# MSP430FR5739 register map
File version: 1.1
CPU: msp430
Registers are 16-bit, access not given, reset 0x0 unless marked. A register's access mark holds for its fields unless they carry their own. Offsets are from the block's base; [hi:lo] are bit positions; {n}, {i} and the like mark numbered series.

## CS__Clock_System
Base 0x00000000
0x160 CSCTL0 — CS Control Register 0
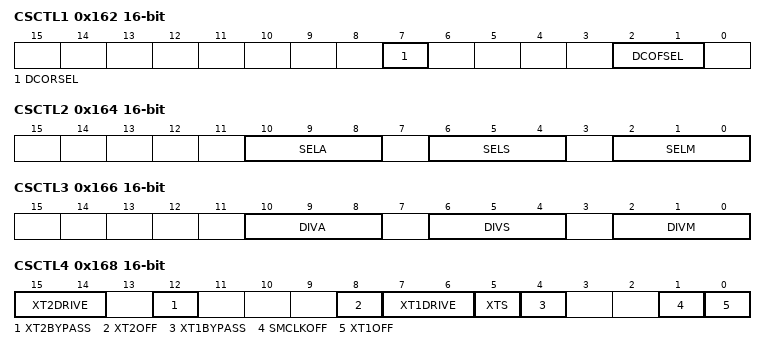
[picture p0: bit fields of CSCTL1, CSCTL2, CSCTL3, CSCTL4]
0x162 CSCTL1 — CS Control Register 1
  [7] DCORSEL — [7:7] DCO range select.
  [2:1] DCOFSEL — [2:1] DCO frequency select Bit: 0
    {v}=DCO frequency select: {v} (v=0..3)
0x164 CSCTL2 — CS Control Register 2
  [10:8] SELA — [10:8] ACLK Source Select Bit: 0
    {v}=ACLK Source Select {v} (v=0..7)
  [6:4] SELS — [6:4] SMCLK Source Select Bit: 0
    {v}=SMCLK Source Select {v} (v=0..7)
  [2:0] SELM — [2:0] MCLK Source Select Bit: 0
    {v}=MCLK Source Select {v} (v=0..7)
0x166 CSCTL3 — CS Control Register 3
  [10:8] DIVA — [10:8] ACLK Divider Bit: 0
    {v}=ACLK Source Divider {v} (v=0..5)
  [6:4] DIVS — [6:4] SMCLK Divider Bit: 0
    {v}=SMCLK Source Divider {v} (v=0..5)
  [2:0] DIVM — [2:0] MCLK Divider Bit: 0
    {v}=MCLK Source Divider {v} (v=0..5)
0x168 CSCTL4 — CS Control Register 4
  [15:14] XT2DRIVE — [15:14] XT2 Drive Level mode Bit 0
    {v}=XT2 Drive Level mode: {v} (v=0..3)
  [12] XT2BYPASS — [12:12] XT2 bypass mode : 0: internal 1:sourced from external pin
  [8] XT2OFF — [8:8] High Frequency Oscillator 2 (XT2) disable
  [7:6] XT1DRIVE — [7:6] XT1 Drive Level mode Bit 0
    {v}=XT1 Drive Level mode: {v} (v=0..3)
  [5] XTS — [5:5] 1: Selects high-freq. oscillator
  [4] XT1BYPASS — [4:4] XT1 bypass mode : 0: internal 1:sourced from external pin
  [1] SMCLKOFF — [1:1] SMCLK Off
  [0] XT1OFF — [0:0] High Frequency Oscillator 1 (XT1) disable
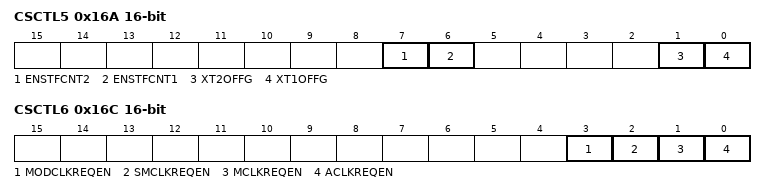
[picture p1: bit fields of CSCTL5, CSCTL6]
0x16A CSCTL5 — CS Control Register 5
  [7] ENSTFCNT2 — [7:7] Enable start counter for XT2
  [6] ENSTFCNT1 — [6:6] Enable start counter for XT1
  [1] XT2OFFG — [1:1] High Frequency Oscillator 2 Fault Flag
  [0] XT1OFFG — [0:0] XT1 Low Frequency Oscillator Fault Flag
0x16C CSCTL6 — CS Control Register 6
  [3] MODCLKREQEN — [3:3] MODOSC Clock Request Enable
  [2] SMCLKREQEN — [2:2] SMCLK Clock Request Enable
  [1] MCLKREQEN — [1:1] MCLK Clock Request Enable
  [0] ACLKREQEN — [0:0] ACLK Clock Request Enable

## CRC16
Base 0x00000000
0x150 CRCDI — CRC Data In Register
0x152 CRCDIRB — CRC data in reverse byte Register
0x154 CRCINIRES — CRC Initialisation Register and Result Register
0x156 CRCRESR — CRC reverse result Register

## DMA
Base 0x00000000
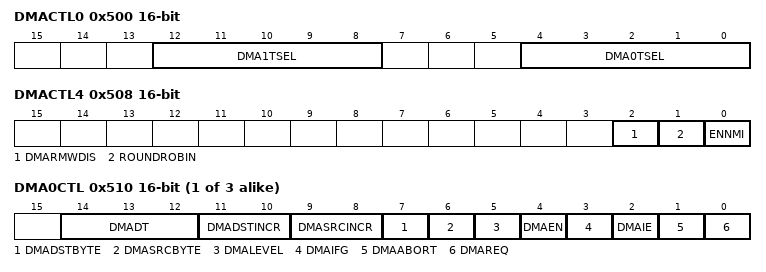
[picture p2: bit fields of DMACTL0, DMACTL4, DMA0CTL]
0x500 DMACTL0 — DMA Module Control 0
  [12:8] DMA1TSEL — [12:8] DMA channel 1 transfer select bit 0
    0=DMA channel 1 transfer select 0: DMA_REQ (sw); {v}=DMA channel 1 transfer select {v}: (v=1..29); 30=DMA channel 1 transfer select 30: previous DMA channel DMA0IFG; 31=DMA channel 1 transfer select 31: ext. Trigger (DMAE0)
  [4:0] DMA0TSEL — [4:0] DMA channel 0 transfer select bit 0
    0=DMA channel 0 transfer select 0: DMA_REQ (sw); {v}=DMA channel 0 transfer select {v}: (v=1..29); 30=DMA channel 0 transfer select 30: previous DMA channel DMA2IFG; 31=DMA channel 0 transfer select 31: ext. Trigger (DMAE0)
0x502 DMACTL1 — DMA Module Control 1
  [4:0] DMA2TSEL — [4:0] DMA channel 2 transfer select bit 0
    0=DMA channel 2 transfer select 0: DMA_REQ (sw); {v}=DMA channel 2 transfer select {v}: (v=1..29); 30=DMA channel 2 transfer select 30: previous DMA channel DMA1IFG; 31=DMA channel 2 transfer select 31: ext. Trigger (DMAE0)
0x504 DMACTL2 — DMA Module Control 2
0x506 DMACTL3 — DMA Module Control 3
0x508 DMACTL4 — DMA Module Control 4
  [2] DMARMWDIS — [2:2] Inhibited DMA transfers during read-modify-write CPU operations
  [1] ROUNDROBIN — [1:1] Round-Robin DMA channel priorities
  [0] ENNMI — [0:0] Enable NMI interruption of DMA
0x50E DMAIV — DMA Interrupt Vector Word
{0x510+0x10*i} DMA{i}CTL (i=0..2) — DMA Channel {i} Control
  [14:12] DMADT — [14:12] DMA transfer mode bit 0
    0=DMA transfer mode 0: Single transfer; 1=DMA transfer mode 1: Block transfer; 2=DMA transfer mode 2: Burst-Block transfer; 3=DMA transfer mode 3: Burst-Block transfer; 4=DMA transfer mode 4: Repeated Single transfer; 5=DMA transfer mode 5: Repeated Block transfer; 6=DMA transfer mode 6: Repeated Burst-Block transfer; 7=DMA transfer mode 7: Repeated Burst-Block transfer
  [11:10] DMADSTINCR — [11:10] DMA destination increment bit 0
    0=DMA destination increment 0: destination address unchanged; 1=DMA destination increment 1: destination address unchanged; 2=DMA destination increment 2: destination address decremented; 3=DMA destination increment 3: destination address incremented
  [9:8] DMASRCINCR — [9:8] DMA source increment bit 0
    0=DMA source increment 0: source address unchanged; 1=DMA source increment 1: source address unchanged; 2=DMA source increment 2: source address decremented; 3=DMA source increment 3: source address incremented
  [7] DMADSTBYTE — [7:7] DMA destination byte
  [6] DMASRCBYTE — [6:6] DMA source byte
  [5] DMALEVEL — [5:5] DMA level sensitive trigger select
  [4] DMAEN — [4:4] DMA enable
  [3] DMAIFG — [3:3] DMA interrupt flag
  [2] DMAIE — [2:2] DMA interrupt enable
  [1] DMAABORT — [1:1] DMA transfer aborted by NMI
  [0] DMAREQ — [0:0] Initiate DMA transfer with DMATSEL
{0x512+0x10*i} DMA{i}SA 32-bit (i=0..2) — DMA Channel {i} Source Address
{0x516+0x10*i} DMA{i}DA 32-bit (i=0..2) — DMA Channel {i} Destination Address
{0x51A+0x10*i} DMA{i}SZ (i=0..2) — DMA Channel {i} Transfer Size
